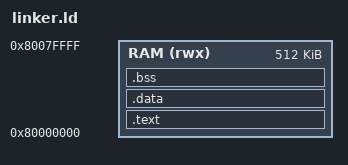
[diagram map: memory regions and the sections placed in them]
ENTRY(_start)

MEMORY
{
  RAM (rwx) : ORIGIN = 0x80000000, LENGTH = 512K
}

SECTIONS
{
  .text : {
    *(.text.init)
    *(.text*)
    *(.rodata*)
  } > RAM

  .data : {
    *(.data*)
  } > RAM

  .bss : {
    __bss_start = .;
    *(.bss*)
    *(COMMON)
    __bss_end = .;
  } > RAM

  . = ALIGN(16);
  __stack_top = ORIGIN(RAM) + LENGTH(RAM);
}
